# DA1470x register map
Vendor: Dialog; Series: DA1470x; File version: 1.2
CPU: CM33 r0p2, little endian, MPU, FPU, DSP, VTOR, 4 interrupt priority bits
Registers are 32-bit, read-write, reset 0x0 unless marked. A register's access mark holds for its fields unless they carry their own. Offsets are from the block's base; [hi:lo] are bit positions; {n}, {i} and the like mark numbered series; 'fields as' and 'values as' point back to an identical list.

## GPIO — GPIO registers
Base 0x50050100
0x00 P0_DATA_REG reset 0x3015 (reset mask 0x7FFFFFFF) — P0 Data input / output Register
  [31:0] P0_DATA — Set P0 output register when written; Returns the value of P0 port when read
0x04 P1_DATA_REG reset 0x20000000 (reset mask 0x7FFFFFFF) — P1 Data input / output Register
  [31:0] P1_DATA — Set P1 output register when written; Returns the value of P1 port when read
0x08 P2_DATA_REG reset 0x6000 — P1 Data input / output Register
  [14:0] P2_DATA — Set P2 output register when written; Returns the value of P2 port when read
0x0C P0_SET_DATA_REG (reset mask 0x7FFFFFFF) — P0 Set port pins Register
  [31:0] P0_SET wo — Writing a 1 to P0[y] sets P0[y] to 1. Writing 0 is discarded; Reading returns 0
0x10 P1_SET_DATA_REG (reset mask 0x7FFFFFFF) — P1 Set port pins Register
  [31:0] P1_SET wo — Writing a 1 to P1[y] sets P1[y] to 1. Writing 0 is discarded; Reading returns 0
0x14 P2_SET_DATA_REG — P1 Set port pins Register
  [14:0] P2_SET wo — Writing a 1 to P2[y] sets P2[y] to 1. Writing 0 is discarded; Reading returns 0
0x18 P0_RESET_DATA_REG (reset mask 0x7FFFFFFF) — P0 Reset port pins Register
  [31:0] P0_RESET wo — Writing a 1 to P0[y] sets P0[y] to 0. Writing 0 is discarded; Reading returns 0
0x1C P1_RESET_DATA_REG (reset mask 0x7FFFFFFF) — P1 Reset port pins Register
  [31:0] P1_RESET wo — Writing a 1 to P1[y] sets P1[y] to 0. Writing 0 is discarded; Reading returns 0
0x20 P2_RESET_DATA_REG — P0 Reset port pins Register
  [14:0] P2_RESET wo — Writing a 1 to P2[y] sets P2[y] to 0. Writing 0 is discarded; Reading returns 0
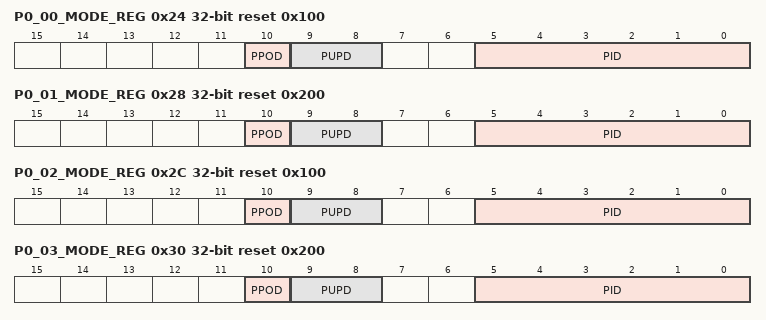
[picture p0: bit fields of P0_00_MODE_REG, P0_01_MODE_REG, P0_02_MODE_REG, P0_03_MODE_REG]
0x24 P0_00_MODE_REG reset 0x100 — P0_00 Mode Register
  [10] PPOD — 0: Push pull 1: Open drain
  [9:8] PUPD — 00 = Input, no resistors selected 01 = Input, pull-up selected 10 = Input, pull-down selected 11 = Output, no resistors selected In ADC mode, these bits are don't care
  [5:0] PID — Function of port: 0: GPIO 1: UART_RX 2: UART_TX 3: UART2_RX 4: UART2_TX 5: UART2_CTSN 6: UART2_RTSN 7: UART3_RX 8: UART3_TX 9: UART3_CTSN / ISO_RST 10: UART3_RTSN / ISO_CARDINSERT 11: ISO_CLK 12: ISO_DATA 13: SPI_DI 14: SPI_DO 15: SPI_CLK 16: SPI_EN 17: SPI_EN2 18: SPI2_DI 19: SPI2_DO 20: SPI2_CLK 21: SPI2_EN 22: SPI2_EN2 23: SPI3_EN 24: SPI3_EN2 25: I2C_SCL 26: I2C_SDA 27: I2C2_SCL 28: I2C2_SDA 29: I2C3_SCL 30: I2C3_SDA 31: I3C_SCL 32: I3C_SDA 33: USB_SOF 34: ADC (Analog) 35: USB (P2_10 and P2_11) 36: PCM_DI 37: PCM_DO 38: PCM_FSC 39: PCM_CLK 40: PDM_DATA 41: PDM_CLK 42: COEX_EXT_ACT 43: COEX_SMART_ACT 44: COEX_SMART_PRI 45: PORT0_DCF 46: PORT1_DCF 47: PORT2_DCF 48: PORT3_DCF 49: PORT4_DCF 50: CLOCK (see also GPIO_CLK_SEL_REG for the dedicated pins mapping of supported clocks) 51: TIM_PWM 52: TIM2_PWM 53: TIM3_PWM 54: TIM4_PWM 55: TIM5_PWM 56: TIM6_PWM 57: TIM_1SHOT 58: TIM2_1SHOT 59: TIM3_1SHOT 60: TIM4_1SHOT 61: TIM5_1SHOT 62: TIM6_1SHOT 63: CMAC_DIAG (Dedicated Pins)
0x28 P0_01_MODE_REG reset 0x200 — P0_01 Mode Register
  [10] PPOD — 0: Push pull 1: Open drain
  [9:8] PUPD — 00 = Input, no resistors selected 01 = Input, pull-up selected 10 = Input, pull-down selected 11 = Output, no resistors selected In ADC mode, these bits are don't care
  [5:0] PID — See P0_00_MODE_REG[PID]
0x2C P0_02_MODE_REG reset 0x100 — P0_02 Mode Register
  fields as P0_01_MODE_REG
0x30 P0_03_MODE_REG reset 0x200 — P0_03 Mode Register
  fields as P0_01_MODE_REG
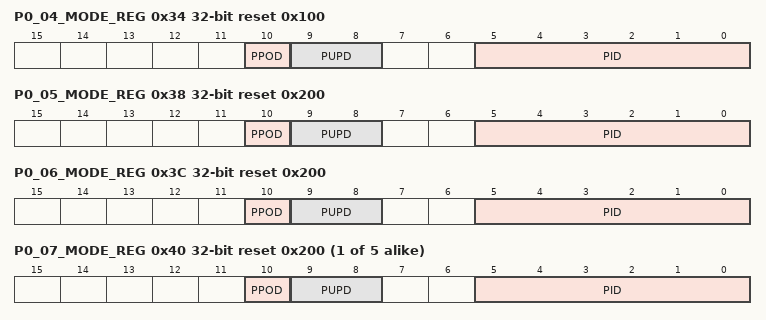
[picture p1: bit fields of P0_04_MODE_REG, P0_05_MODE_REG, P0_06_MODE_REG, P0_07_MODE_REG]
0x34 P0_04_MODE_REG reset 0x100 — P0_04 Mode Register
  fields as P0_01_MODE_REG
0x38 P0_05_MODE_REG reset 0x200 — P0_05 Mode Register
  fields as P0_01_MODE_REG
0x3C P0_06_MODE_REG reset 0x200 — P0_06 Mode Register
  fields as P0_01_MODE_REG
{0x24+4i} P0_{i:02}_MODE_REG reset 0x200 (i=7..11) — P0_{i:02} Mode Register
  [10] PPOD — 0: Push pull 1: Open drain
  [9:8] PUPD — 00 = Input, no resistors selected 01 = Input, pull-up selected 10 = Input, pull-down selected 11 = Output, no resistors selected In ADC mode, these bits are don't care.
  [5:0] PID — See P0_00_MODE_REG[PID]
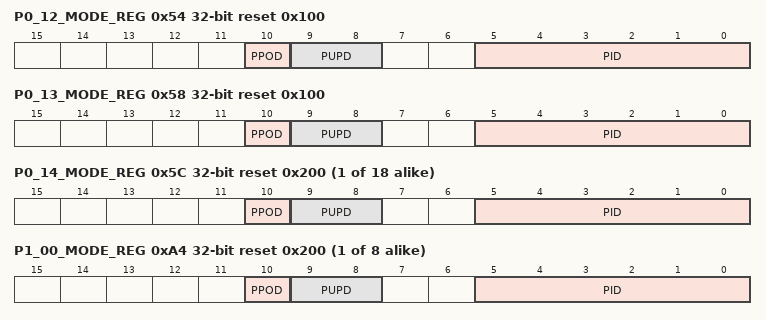
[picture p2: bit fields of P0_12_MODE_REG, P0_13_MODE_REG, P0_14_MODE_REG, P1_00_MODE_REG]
0x54 P0_12_MODE_REG reset 0x100 — P0_12 Mode Register
  fields as P0_07_MODE_REG
0x58 P0_13_MODE_REG reset 0x100 — P0_13 Mode Register
  fields as P0_07_MODE_REG
{0x24+4i} P0_{i}_MODE_REG reset 0x200 (i=14..31) — P0_{i} Mode Register
  fields as P0_07_MODE_REG
{0xA4+4i} P1_{i:02}_MODE_REG reset 0x200 (i=0..7) — P1_{i:02} Mode Register
  fields as P0_01_MODE_REG
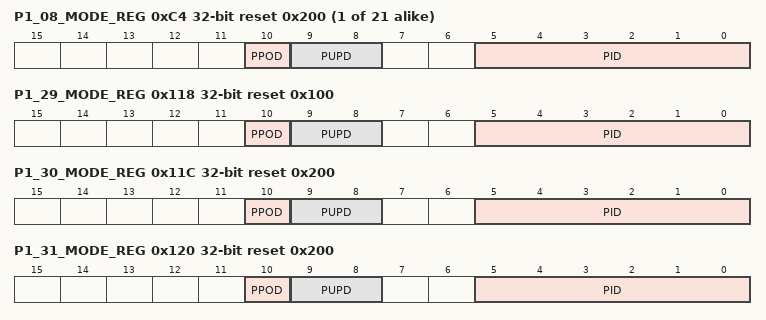
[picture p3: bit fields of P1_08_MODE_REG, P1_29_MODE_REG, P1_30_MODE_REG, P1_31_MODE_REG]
{0xA4+4i} P1_{i:02}_MODE_REG reset 0x200 (i=8..28) — P1_{i:02} Mode Register
  fields as P0_07_MODE_REG
0x118 P1_29_MODE_REG reset 0x100 — P1_29 Mode Register
  fields as P0_07_MODE_REG
0x11C P1_30_MODE_REG reset 0x200 — P1_30 Mode Register
  fields as P0_07_MODE_REG
0x120 P1_31_MODE_REG reset 0x200 — P1_31 Mode Register
  fields as P0_07_MODE_REG
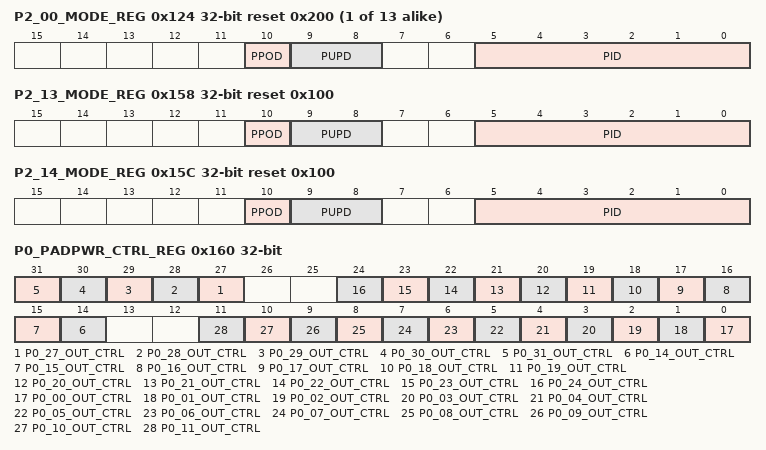
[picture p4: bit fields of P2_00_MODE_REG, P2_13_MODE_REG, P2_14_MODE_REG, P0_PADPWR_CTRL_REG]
{0x124+4i} P2_{i:02}_MODE_REG reset 0x200 (i=0..12) — P2_{i:02} Mode Register
  fields as P0_07_MODE_REG
0x158 P2_13_MODE_REG reset 0x100 — P2_13 Mode Register
  fields as P0_07_MODE_REG
0x15C P2_14_MODE_REG reset 0x100 — P2_14 Mode Register
  fields as P0_07_MODE_REG
0x160 P0_PADPWR_CTRL_REG (reset mask 0x7FFFFFFF) — P0 Output Power Control Register
  [n] P0_{n}_OUT_CTRL (n=27..31) — 0 = P0_{n} port output is powered by the V30 rail (default) 1 = P0_{n} port output is powered by the 1V8P rail Bit {n} controls the power supply of P0_{n}.
  [n] P0_{n}_OUT_CTRL (n=14..24) — 0 = P0_{n} port output is powered by the V30 rail (default) 1 = P0_{n} port output is powered by the 1V8P rail Bit {n} controls the power supply of P0_{n}.
  [n] P0_{n:02}_OUT_CTRL (n=0..11) — 0 = P0_{n:02} port output is powered by the V30 rail (default) 1 = P0_{n:02} port output is powered by the 1V8P rail Bit {n} controls the power supply of P0_{n:02}.
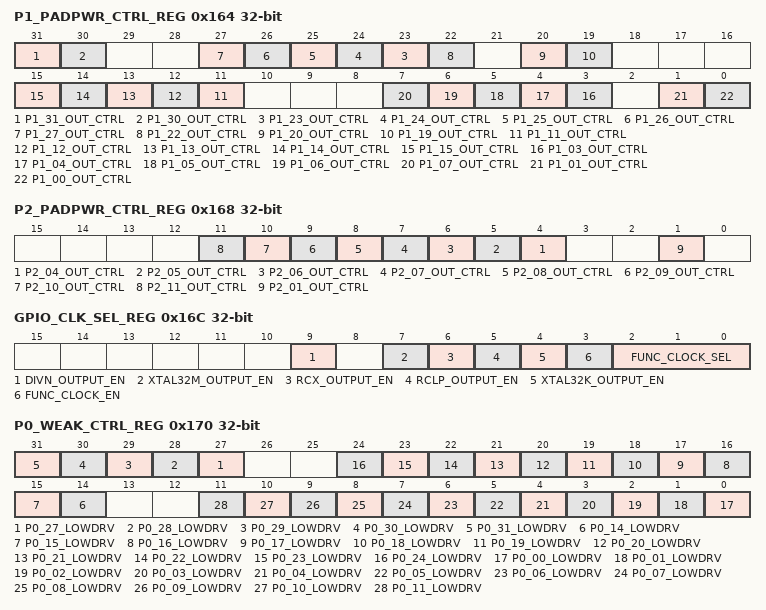
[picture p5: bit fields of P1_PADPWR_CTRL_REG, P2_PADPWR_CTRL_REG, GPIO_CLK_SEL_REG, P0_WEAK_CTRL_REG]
0x164 P1_PADPWR_CTRL_REG (reset mask 0x7FFFFFFF) — P1 Output Power Control Register
  [31] P1_31_OUT_CTRL — 0 = P1_31 port output is powered by the V30 rail (default) 1 = P1_31 port output is powered by the 1V8P rail Bit 31 controls the power supply of P1_31.
  [30] P1_30_OUT_CTRL — 0 = P1_30 port output is powered by the V30 rail (default) 1 = P1_30 port output is powered by the 1V8P rail Bit 30 controls the power supply of P1_30.
  [n] P1_{n}_OUT_CTRL (n=23..27) — 0 = P1_{n} port output is powered by the V30 rail (default) 1 = P1_{n} port output is powered by the 1V8P rail Bit {n} controls the power supply of P1_{n}.
  [22] P1_22_OUT_CTRL — 0 = P1_22 port output is powered by the V30 rail (default) 1 = P1_22 port output is powered by the 1V8P rail Bit 30 controls the power supply of P1_22.
  [20] P1_20_OUT_CTRL — 0 = P1_20 port output is powered by the V30 rail (default) 1 = P1_20 port output is powered by the 1V8P rail Bit 20 controls the power supply of P1_20.
  [19] P1_19_OUT_CTRL — 0 = P1_19 port output is powered by the V30 rail (default) 1 = P1_19 port output is powered by the 1V8P rail Bit 19 controls the power supply of P1_19.
  [n] P1_{n}_OUT_CTRL (n=11..15) — 0 = P1_{n} port output is powered by the V30 rail (default) 1 = P1_{n} port output is powered by the 1V8P rail Bit {n} controls the power supply of P1_{n}.
  [n] P1_{n:02}_OUT_CTRL (n=3..7) — 0 = P1_{n:02} port output is powered by the V30 rail (default) 1 = P1_{n:02} port output is powered by the 1V8P rail Bit {n} controls the power supply of P1_{n:02}.
  [1] P1_01_OUT_CTRL — 0 = P1_01 port output is powered by the V30 rail (default) 1 = P1_01 port output is powered by the 1V8P rail Bit 1 controls the power supply of P1_01.
  [0] P1_00_OUT_CTRL — 0 = P1_00 port output is powered by the V30 rail (default) 1 = P1_00 port output is powered by the 1V8P rail Bit 0 controls the power supply of P1_00.
0x168 P2_PADPWR_CTRL_REG — P2 Output Power Control Register
  [n] P2_{n:02}_OUT_CTRL (n=4..11) — 0 = P2_{n:02} port output is powered by the V30 rail (default) 1 = P2_{n:02} port output is powered by the 1V8P rail Bit {n} controls the power supply of P2_{n:02}.
  [1] P2_01_OUT_CTRL — 0 = P2_01 port output is powered by the V30 rail (default) 1 = P2_01 port output is powered by the 1V8P rail Bit 1 controls the power supply of P2_01.
0x16C GPIO_CLK_SEL_REG — Select which clock to map on ports P0/P1
  [9] DIVN_OUTPUT_EN — DIVN output enable bit-field. When set, it enables the mapping of DIVN clock on dedicated GPIO (P0_20). The specific GPIO must be configured as GPIO output.
  [7] XTAL32M_OUTPUT_EN — XTAL32M output enable bit-field. When set, it enables the mapping of XTAL32M clock on dedicated GPIO (P1_04). The specific GPIO must be configured as GPIO output.
  [6] RCX_OUTPUT_EN — RCX output enable bit-field. When set, it enables the mapping of RCX clock on dedicated GPIO (P1_22). The specific GPIO must be configured as GPIO output.
  [5] RCLP_OUTPUT_EN — RCLP output enable bit-field. When set, it enables the mapping of RCLP clock on dedicated GPIO (P1_23). The specific GPIO must be configured as GPIO output.
  [4] XTAL32K_OUTPUT_EN — XTAL32K output enable bit-field. When set, it enables the mapping of XTAL32K clock on dedicated GPIO (P0_31).The specific GPIO must be configured as GPIO output.
  [3] FUNC_CLOCK_EN — If set, it enables the mapping of the selected clock signal, according to FUNC_CLOCK_SEL bit-field. The clock can be mapped to any GPIO (PX_YY), as long as PX_YY_MODE_REG[PID]= (FUNC_CLOCK) and PX_YY_MODE_REG[PUPD]=3 (Output). Bits 4-9 are ignored in this case. If not set, then each clock is mapped to a dedicated GPIO, according to bits 4-9."
  [2:0] FUNC_CLOCK_SEL — Select which clock to map when PID = FUNC_CLOCK. 0x0: XTAL32K 0x1: RCLP 0x2: RCX 0x3: XTAL32M 0x4: DIVN 0x5: Reserved 0x6: Reserved 0x7: Reserved FUNC_CLOCK_EN = 1 else masked
0x170 P0_WEAK_CTRL_REG (reset mask 0x7FFFFFFF) — P0 Weak Pads Control Register
  [n] P0_{n}_LOWDRV (n=27..31) — 0 = Normal operation 1 = Reduces the driving strength of P0_{n} pad Note: This mode should be coupled with the selection of VDD1V8P supply rail for the specific pad (see also the description of P0_PADPWDR_CTRL_REG).
  [n] P0_{n}_LOWDRV (n=14..24) — 0 = Normal operation 1 = Reduces the driving strength of P0_{n} pad Note: This mode should be coupled with the selection of VDD1V8P supply rail for the specific pad (see also the description of P0_PADPWDR_CTRL_REG).
  [n] P0_{n:02}_LOWDRV (n=0..11) — 0 = Normal operation 1 = Reduces the driving strength of P0_{n:02} pad Note: This mode should be coupled with the selection of VDD1V8P supply rail for the specific pad (see also the description of P0_PADPWDR_CTRL_REG).
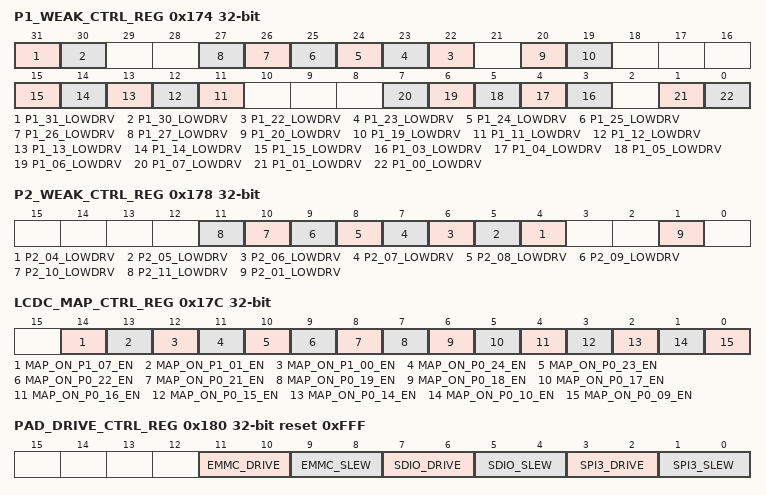
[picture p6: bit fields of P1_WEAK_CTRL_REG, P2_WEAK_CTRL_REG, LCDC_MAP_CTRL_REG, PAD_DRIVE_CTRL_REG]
0x174 P1_WEAK_CTRL_REG (reset mask 0x7FFFFFFF) — P1 Weak Pads Control Register
  [31] P1_31_LOWDRV — 0 = Normal operation 1 = Reduces the driving strength of P1_30 pad Note: This mode should be coupled with the selection of VDD1V8P supply rail for the specific pad (see also the description of P1_PADPWDR_CTRL_REG).
  [30] P1_30_LOWDRV — 0 = Normal operation 1 = Reduces the driving strength of P1_30 pad Note: This mode should be coupled with the selection of VDD1V8P supply rail for the specific pad (see also the description of P1_PADPWDR_CTRL_REG).
  [n] P1_{n}_LOWDRV (n=22..27) — 0 = Normal operation 1 = Reduces the driving strength of P1_{n} pad Note: This mode should be coupled with the selection of VDD1V8P supply rail for the specific pad (see also the description of P1_PADPWDR_CTRL_REG).
  [20] P1_20_LOWDRV — 0 = Normal operation 1 = Reduces the driving strength of P1_20 pad Note: This mode should be coupled with the selection of VDD1V8P supply rail for the specific pad (see also the description of P1_PADPWDR_CTRL_REG).
  [19] P1_19_LOWDRV — 0 = Normal operation 1 = Reduces the driving strength of P1_19 pad Note: This mode should be coupled with the selection of VDD1V8P supply rail for the specific pad (see also the description of P1_PADPWDR_CTRL_REG).
  [n] P1_{n}_LOWDRV (n=11..15) — 0 = Normal operation 1 = Reduces the driving strength of P1_{n} pad Note: This mode should be coupled with the selection of VDD1V8P supply rail for the specific pad (see also the description of P1_PADPWDR_CTRL_REG).
  [n] P1_{n:02}_LOWDRV (n=3..7) — 0 = Normal operation 1 = Reduces the driving strength of P1_{n:02} pad Note: This mode should be coupled with the selection of VDD1V8P supply rail for the specific pad (see also the description of P1_PADPWDR_CTRL_REG).
  [1] P1_01_LOWDRV — 0 = Normal operation 1 = Reduces the driving strength of P1_01 pad Note: This mode should be coupled with the selection of VDD1V8P supply rail for the specific pad (see also the description of P1_PADPWDR_CTRL_REG).
  [0] P1_00_LOWDRV — 0 = Normal operation 1 = Reduces the driving strength of P1_00 pad Note: This mode should be coupled with the selection of VDD1V8P supply rail for the specific pad (see also the description of P1_PADPWDR_CTRL_REG).
0x178 P2_WEAK_CTRL_REG — P2 Weak Pads Control Register
  [n] P2_{n:02}_LOWDRV (n=4..11) — 0 = Normal operation 1 = Reduces the driving strength of P2_{n:02} pad Note: This mode should be coupled with the selection of VDD1V8P supply rail for the specific pad (see also the description of P2_PADPWDR_CTRL_REG).
  [1] P2_01_LOWDRV — 0 = Normal operation 1 = Reduces the driving strength of P2_01 pad Note: This mode should be coupled with the selection of VDD1V8P supply rail for the specific pad (see also the description of P2_PADPWDR_CTRL_REG).
0x17C LCDC_MAP_CTRL_REG — LCDC mapping control Register
  [14] MAP_ON_P1_07_EN — 0 = Normal operation 1 = Enables the mapping of LCDC signals on P1_07, overruling P1_07_MODE_REG. The signals mapped, depending on the mode, are the following: - JDI LCD I/F : Not applicable - MIPI DPI-2 : Not applicable - MIPI DBI-B : DBIB_DB7 (direction controlled by the LCDC DBI-B I/F) - LCD SPI I/F : Not applicable
  [13] MAP_ON_P1_01_EN — 0 = Normal operation 1 = Enables the mapping of LCDC signals on P1_01, overruling P1_01_MODE_REG. The signals mapped, depending on the mode, are the following: - JDI LCD I/F : BLUE0 (Output) - MIPI DPI-2 : DPI_BLUE0 (DATA[4]) (Output) - MIPI DBI-B : DBIB_DB4 (direction controlled by the LCDC DBI-B I/F) - LCD SPI I/F : Not applicable
  [12] MAP_ON_P1_00_EN — 0 = Normal operation 1 = Enables the mapping of LCDC signals on P1_00, overruling P1_00_MODE_REG. The signals mapped, depending on the mode, are the following: - JDI LCD I/F : GREEN1 (Output) - MIPI DPI-2 : DPI_GREEN1 (DATA[3]) (Output) - MIPI DBI-B : DBIB_DB3 (direction controlled by the LCDC DBI-B I/F) - LCD SPI I/F : Not applicable
  [11] MAP_ON_P0_24_EN — 0 = Normal operation 1 = Enables the mapping of LCDC signals on P0_24, overruling P0_24_MODE_REG. The signals mapped, depending on the mode, are the following: - JDI LCD I/F : GREEN0 (Output) - MIPI DPI-2 : DPI_GREEN0 (DATA[2]) (Output) - MIPI DBI-B : DBIB_DB2 (direction controlled by the LCDC DBI-B I/F) - LCD SPI I/F : Not applicable
  [10] MAP_ON_P0_23_EN — 0 = Normal operation 1 = Enables the mapping of LCDC signals on P0_23, overruling P0_23_MODE_REG. The signals mapped, depending on the mode, are the following: - JDI LCD I/F : RED1 (Output) - MIPI DPI-2 : DPI_RED1 (DATA[1]) (Output) - MIPI DBI-B : DBIB_DB1 (direction controlled by the LCDC DBI-B I/F) - LCD SPI I/F : Not applicable
  [9] MAP_ON_P0_22_EN — 0 = Normal operation 1 = Enables the mapping of LCDC signals on P0_22, overruling P0_22_MODE_REG. The signals mapped, depending on the mode, are the following: - JDI LCD I/F : XRST (Output) - MIPI DPI-2 : DPI_SD (Output) - MIPI DBI-B : DBIB_RDX (Output) - LCD SPI I/F : LCD_SPI_SD2 (Output)
  [8] MAP_ON_P0_21_EN — 0 = Normal operation 1 = Enables the mapping of LCDC signals on P0_21, overruling P0_21_MODE_REG. The signals mapped, depending on the mode, are the following: - JDI LCD I/F : BLUE1 (Output) - MIPI DPI-2 : DPI_BLUE1 (DATA[5]) (Output) - MIPI DBI-B : DBIB_DB5 (direction controlled by the LCDC DBI-B I/F) - LCD SPI I/F : Not applicable
  [7] MAP_ON_P0_19_EN — 0 = Normal operation 1 = Enables the mapping of LCDC signals on P0_19, overruling P0_19_MODE_REG. The signals mapped, depending on the mode, are the following: - JDI LCD I/F : VCOM/FRP (Input) - MIPI DPI-2 : Not applicable - MIPI DBI-B : DBIB_DB6 (direction controlled by the LCDC DBI-B I/F) - LCD SPI I/F : EXTCOMIN (Input)
  [6] MAP_ON_P0_18_EN — 0 = Normal operation 1 = Enables the mapping of LCDC signals on P0_18, overruling P0_18_MODE_REG. The signals mapped, depending on the mode, are the following: - JDI LCD I/F : ENB (Output) - MIPI DPI-2 : DPI_DE (Output) - MIPI DBI-B : DBIB_RESX (Output) - LCD SPI I/F : LCD_SPI_CS (Output)
  [5] MAP_ON_P0_17_EN — 0 = Normal operation 1 = Enables the mapping of LCDC signals on P0_17, overruling P0_17_MODE_REG. The signals mapped, depending on the mode, are the following: - JDI LCD I/F : RED0 (Output) - MIPI DPI-2 : DPI_RED0 (DATA[0]) (Output) - MIPI DBI-B : DBIB_DB0 (direction controlled by the LCDC DBI-B I/F) - LCD SPI I/F : LCD_SPI_SD3 (Output)
  [4] MAP_ON_P0_16_EN — 0 = Normal operation 1 = Enables the mapping of LCDC signals on P0_16, overruling P0_16_MODE_REG. The signals mapped, depending on the mode, are the following: - JDI LCD I/F : VST (Output) - MIPI DPI-2 : DPI_VSYNC (Output) - MIPI DBI-B : DBIB_WRX (Output) - LCD SPI I/F : LCD_SPI_SD1 (Output)
  [3] MAP_ON_P0_15_EN — 0 = Normal operation 1 = Enables the mapping of LCDC signals on P0_15, overruling P0_15_MODE_REG. The signals mapped, depending on the mode, are the following: - JDI LCD I/F : HST (Output) - MIPI DPI-2 : DPI_HSYNC (Output) - MIPI DBI-B : DBIB_D/CS (Output) - LCD SPI I/F : LCD_SPI_SD (direction controlled by the LCDC SPI I/F)
  [2] MAP_ON_P0_14_EN — 0 = Normal operation 1 = Enables the mapping of LCDC signals on P0_14, overruling P0_14_MODE_REG. The signals mapped, depending on the mode, are the following: - JDI LCD I/F : HCK (Output) - MIPI DPI-2 : DPI_CLK (Output) - MIPI DBI-B : DBIB_CSX (Output) - LCD SPI I/F : LCD_SPI_SCLK (Output)
  [1] MAP_ON_P0_10_EN — 0 = Normal operation 1 = Enables the mapping of LCDC signals on P0_10, overruling P0_10_MODE_REG. The signals mapped, depending on the mode, are the following: - JDI LCD I/F : XFRP (Input) - MIPI DPI-2 : DPI_READY (Input) - MIPI DBI-B : DBIB_TE (Input) - LCD SPI I/F : LCD_TE (Input)
  [0] MAP_ON_P0_09_EN — 0 = Normal operation 1 = Enables the mapping of LCDC signals on P0_09, overruling P0_09_MODE_REG. The signals mapped, depending on the mode, are the following: - JDI LCD I/F : VCK (Output) - MIPI DPI-2 : DPI_CM (Output) - MIPI DPI-B : DBIB_STALL (Input) - LCD SPI I/F : LCD_SPI_SI (Input)
0x180 PAD_DRIVE_CTRL_REG reset 0xFFF — Pad drive control for SPI3/SDIO/eMMC
  [11:10] EMMC_DRIVE — pads drive current 0: 4 mA 1: 8 mA 2: 12 mA 3: 16 mA
  [9:8] EMMC_SLEW — pads slew rate control. Indicative values under certain conditions: 0: Rise=1.7 V/ns, Fall=1.9 V/ns (weak) 1: Rise=2.0 V/ns, Fall=2.3 V/ns 2: Rise=2.3 V/ns, Fall=2.6 V/ns 3: Rise=2.4 V/ns, Fall=2.7 V/ns (strong) Conditions: external pin capacitance 6 pF, Vcc=1.8V, T=25C and Idrive=16mA.
  [7:6] SDIO_DRIVE — pads drive current 0: 4 mA 1: 8 mA 2: 12 mA 3: 16 mA
  [5:4] SDIO_SLEW — QSPI pads slew rate control. Indicative values under certain conditions: 0: Rise=1.7 V/ns, Fall=1.9 V/ns (weak) 1: Rise=2.0 V/ns, Fall=2.3 V/ns 2: Rise=2.3 V/ns, Fall=2.6 V/ns 3: Rise=2.4 V/ns, Fall=2.7 V/ns (strong) Conditions: FLASH pin capacitance 6 pF, Vcc=1.8V, T=25C and Idrive=16mA.
  [3:2] SPI3_DRIVE — pads drive current 0: 4 mA 1: 8 mA 2: 12 mA 3: 16 mA
  [1:0] SPI3_SLEW — QSPI pads slew rate control. Indicative values under certain conditions: 0: Rise=1.7 V/ns, Fall=1.9 V/ns (weak) 1: Rise=2.0 V/ns, Fall=2.3 V/ns 2: Rise=2.3 V/ns, Fall=2.6 V/ns 3: Rise=2.4 V/ns, Fall=2.7 V/ns (strong) Conditions: FLASH pin capacitance 6 pF, Vcc=1.8V, T=25C and Idrive=16mA.
